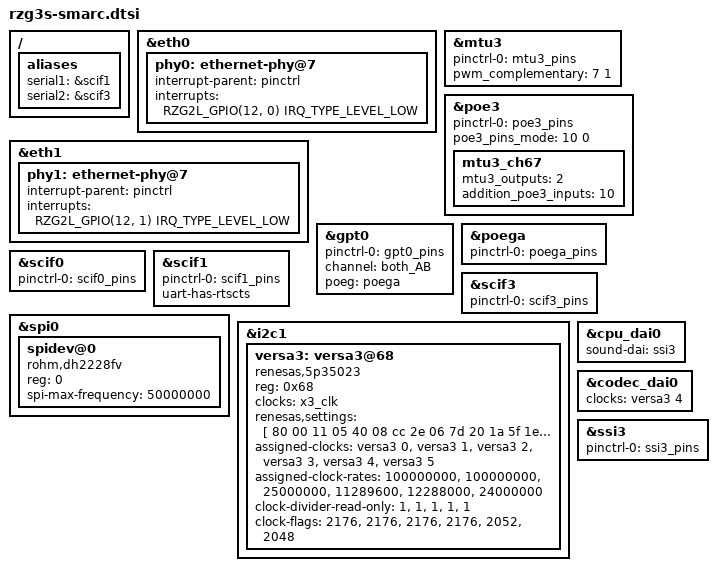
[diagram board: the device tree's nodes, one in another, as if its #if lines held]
// SPDX-License-Identifier: (GPL-2.0-only OR BSD-2-Clause)
/*
 * Device Tree Source for the RZ/G3S SMARC-II board
 *
 * Copyright (C) 2023 Renesas Electronics Corp.
 */

#include "rz-smarc2-common.dtsi"
#include "rzg3s-smarc-pinfunction.dtsi"

/ {
	aliases {
		serial1 = &scif1;
		serial2 = &scif3;
	};
};

#if !SD2_SEL
&eth0 {
	phy0: ethernet-phy@7 {
		interrupt-parent = <&pinctrl>;
		interrupts = <RZG2L_GPIO(12, 0) IRQ_TYPE_LEVEL_LOW>; /* RZ_IRQ0 */
	};
};

&eth1 {
	phy1: ethernet-phy@7 {
		interrupt-parent = <&pinctrl>;
		interrupts = <RZG2L_GPIO(12, 1) IRQ_TYPE_LEVEL_LOW>; /* RZ_IRQ1 */
	};
};
#endif

&mtu3 {
#if MTU3_PWM_SUPPORT
	pinctrl-0 = <&mtu3_pins>;
	pinctrl-names = "default";

#if MTU3_COMPLEMENTARY_PWM_SEL
	pwm_complementary = <7 1>;
#else
	pwm_mode1 = <7 1>;
#endif
#endif

	status = "okay";
};

#if MTU3_COMPLEMENTARY_PWM_SEL
&poe3 {
	pinctrl-0 = <&poe3_pins>;
	pinctrl-names = "default";
	poe3_pins_mode = <10 0>;

	status = "okay";

	mtu3_ch67 {
		mtu3_outputs = <2>;
		addition_poe3_inputs = <10>;
	};
};
#endif

&gpt0 {
	pinctrl-0 = <&gpt0_pins>;
	pinctrl-names = "default";
	channel = "both_AB";
	poeg = <&poega>;
	status = "okay";
};

&poega {
	pinctrl-0 = <&poega_pins>;
	pinctrl-names = "default";
	status = "okay";
};

&scif0 {
	pinctrl-0 = <&scif0_pins>;
	pinctrl-names = "default";
	status = "okay";
};

/* Be noticed that SW_OP_MUX[4] must be turned on to use SCIF1(SER0) at PMOD1-3A. */
#if !SD2_SEL && !SPDIF_SEL
&scif1 {
	pinctrl-0 = <&scif1_pins>;
	pinctrl-names = "default";
	uart-has-rtscts;
	status = "okay";
};
#elif SPDIF_SEL
&cpu_dai1 {
	sound-dai = <&spdif>;
};

&spdif {
	pinctrl-0 = <&spdif_pins>;
	pinctrl-names = "default";
	status = "okay";
};
#endif

&scif3 {
	pinctrl-0 = <&scif3_pins>;
	pinctrl-names = "default";
	status = "okay";
};

&spi0 {
#if RSPI0_LOOPBACK_SEL
	spidev@0 {
		compatible = "rohm,dh2228fv";
		reg = <0>;
		spi-max-frequency = <50000000>;
	};
#else
	flash0: n25q256a@0 {
		compatible = "micron,n25q256a", "jedec,spi-nor";
		reg = <0>;
		spi-max-frequency = <10000000>;
		spi-tx-bus-width = <1>;
		spi-rx-bus-width = <1>;
		m25p,fast-read;

		partitions {
			compatible = "fixed-partitions";
			#address-cells = <1>;
			#size-cells = <1>;

			scratch@0 {
				reg = <0x00000000 0x2000000>;
			};
		};
	};
#endif
};

&i2c1 {
	status = "okay";

	versa3: versa3@68 {
		compatible = "renesas,5p35023";
		reg = <0x68>;
		#clock-cells = <1>;
		clocks = <&x3_clk>;
		clock-names = "x1";
		renesas,settings = [
		  80 00 11 05 40 08 cc 2e 06 7d 20 1a 5f 1e f2 27
		  00 34 af 4f 00 00 00 00 04 0c 1c 18 3f 30 90 c6
		  80 80 30 30 95
		];
		assigned-clocks = <&versa3 0>,
				   <&versa3 1>,
				   <&versa3 2>,
				   <&versa3 3>,
				   <&versa3 4>,
				   <&versa3 5>;
		assigned-clock-rates =	<100000000>, <100000000>,
					<25000000>, <11289600>,
					<12288000>, <24000000>;
		clock-divider-read-only = <1>, <1>, <1>, <1>, <1>;
		clock-flags = <2176>, <2176>, <2176>, <2176>, <2052>, <2048>;
	};
};

&cpu_dai0 {
	sound-dai = <&ssi3>;
};

&codec_dai0 {
	clocks = <&versa3 4>;
};

&ssi3 {
	pinctrl-0 = <&ssi3_pins>;
	pinctrl-names = "default";

	status = "okay";
};
